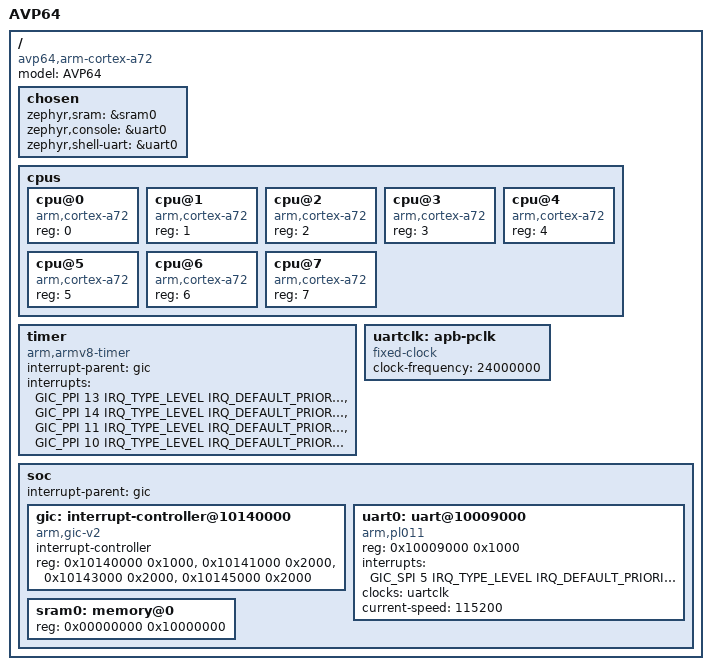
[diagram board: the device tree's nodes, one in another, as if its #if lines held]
/******************************************************************************
 *                                                                            *
 * Copyright 2024 Nils Bosbach                                                *
 *                                                                            *
 * This software is licensed under the Apache license.                        *
 * A copy of the license can be found in the LICENSE file at the root         *
 * of the source tree.                                                        *
 *                                                                            *
 ******************************************************************************/

/dts-v1/;

#include <mem.h>
#include <arm64/armv8-a.dtsi>
#include <dt-bindings/interrupt-controller/arm-gic.h>

/ {
	model = "AVP64";
	compatible = "avp64,arm-cortex-a72";

	chosen {
		zephyr,sram = &sram0;
		zephyr,console = &uart0;
		zephyr,shell-uart = &uart0;
	};

	cpus {
		#address-cells = <1>;
		#size-cells = <0>;

		cpu@0 {
			device_type = "cpu";
			compatible = "arm,cortex-a72";
			reg = <0>;
		};
#if NR_CPU > 1
		cpu@1 {
			device_type = "cpu";
			compatible = "arm,cortex-a72";
			reg = <1>;
		};
#if NR_CPU > 2
		cpu@2 {
			device_type = "cpu";
			compatible = "arm,cortex-a72";
			reg = <2>;
		};
		cpu@3 {
			device_type = "cpu";
			compatible = "arm,cortex-a72";
			reg = <3>;
		};
#if NR_CPU > 4
		cpu@4 {
			device_type = "cpu";
			compatible = "arm,cortex-a72";
			reg = <4>;
		};
		cpu@5 {
			device_type = "cpu";
			compatible = "arm,cortex-a72";
			reg = <5>;
		};
		cpu@6 {
			device_type = "cpu";
			compatible = "arm,cortex-a72";
			reg = <6>;
		};
		cpu@7 {
			device_type = "cpu";
			compatible = "arm,cortex-a72";
			reg = <7>;
		};
#endif
#endif
#endif
	};

	timer {
		compatible = "arm,armv8-timer";
		interrupt-parent = <&gic>;
		interrupts = <GIC_PPI 13 IRQ_TYPE_LEVEL IRQ_DEFAULT_PRIORITY>,
			         <GIC_PPI 14 IRQ_TYPE_LEVEL IRQ_DEFAULT_PRIORITY>,
			     	 <GIC_PPI 11 IRQ_TYPE_LEVEL IRQ_DEFAULT_PRIORITY>,
			     	 <GIC_PPI 10 IRQ_TYPE_LEVEL IRQ_DEFAULT_PRIORITY>;
	};

	uartclk: apb-pclk {
		compatible = "fixed-clock";
		clock-frequency = <24000000>;
		#clock-cells = <0>;
	};

	soc {
		interrupt-parent = <&gic>;

		gic: interrupt-controller@10140000 {
			compatible = "arm,gic-v2", "arm,gic";
			#interrupt-cells = <4>;
            #address-cells = <2>;
            #size-cells = <2>;
			interrupt-controller;
            reg = <0x10140000 0x1000>, // GICD
                  <0x10141000 0x2000>, // GICC
                  <0x10143000 0x2000>, // GICVI
                  <0x10145000 0x2000>; // GICVC
			status = "okay";
		};

		uart0: uart@10009000 {
			compatible = "arm,pl011";
			reg = <0x10009000 0x1000>;
			interrupts = <GIC_SPI 5 IRQ_TYPE_LEVEL IRQ_DEFAULT_PRIORITY>;
			interrupt-names = "irq_0";
			clocks = <&uartclk>;
			status = "okay";
			current-speed = <115200>;
		};

		sram0: memory@0 {
			device_type= "memory";
			reg = <0x00000000 0x10000000>;
		};
	};
};
